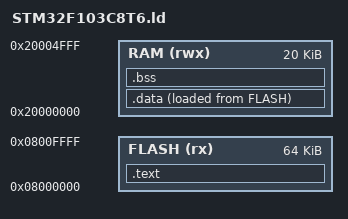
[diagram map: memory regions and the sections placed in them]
/* Linker script for STM32F103C8T6 */
MEMORY
{
    FLASH (rx) : ORIGIN = 0x08000000, LENGTH = 64K
    RAM (rwx)  : ORIGIN = 0x20000000, LENGTH = 20K
}

ENTRY(Reset_Handler)

SECTIONS
{
    .text :
    {
        KEEP(*(.isr_vector))
        *(.text*)
        *(.rodata*)
        . = ALIGN(4);
    } > FLASH

    .data :
    {
        _sdata = .;
        *(.data*)
        . = ALIGN(4);
        _edata = .;
    } > RAM AT> FLASH

    _sidata = LOADADDR(.data);

    .bss :
    {
        _sbss = .;
        *(.bss*)
        *(COMMON)
        . = ALIGN(4);
        _ebss = .;
    } > RAM

    . = ALIGN(8);
    _end = .;
}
